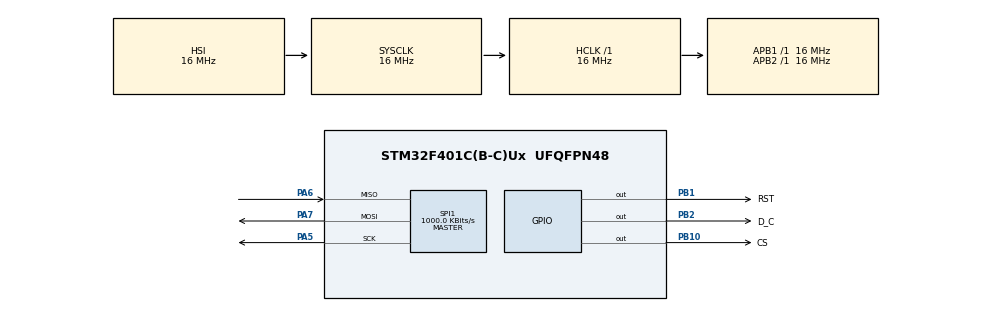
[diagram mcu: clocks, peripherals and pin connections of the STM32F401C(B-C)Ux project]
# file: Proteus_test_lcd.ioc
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Dma.Request0=SPI1_TX
Dma.SPI1_TX.0.Direction=DMA_MEMORY_TO_PERIPH
Dma.SPI1_TX.0.FIFOMode=DMA_FIFOMODE_DISABLE
Dma.SPI1_TX.0.Instance=DMA2_Stream3
Dma.SPI1_TX.0.MemDataAlignment=DMA_MDATAALIGN_BYTE
Dma.SPI1_TX.0.MemInc=DMA_MINC_ENABLE
Dma.SPI1_TX.0.Mode=DMA_NORMAL
Dma.SPI1_TX.0.PeriphDataAlignment=DMA_PDATAALIGN_BYTE
Dma.SPI1_TX.0.PeriphInc=DMA_PINC_DISABLE
Dma.SPI1_TX.0.Priority=DMA_PRIORITY_LOW
Mcu.Family=STM32F4
Mcu.Name=STM32F401C(B-C)Ux
Mcu.Package=UFQFPN48
NVIC.DMA2_Stream3_IRQn=true\:0\:0\:false\:false\:true\:false\:true\:true
NVIC.PriorityGroup=NVIC_PRIORITYGROUP_4
PA5.Mode=Full_Duplex_Master
PA5.Signal=SPI1_SCK
PA6.Mode=Full_Duplex_Master
PA6.Signal=SPI1_MISO
PA7.Mode=Full_Duplex_Master
PA7.Signal=SPI1_MOSI
PB1.GPIO_Label=RST
PB1.Signal=GPIO_Output
PB10.GPIO_Label=CS
PB10.Signal=GPIO_Output
PB2.GPIO_Label=D_C
PB2.Signal=GPIO_Output
ProjectManager.HeapSize=0x200
ProjectManager.StackSize=0x400
ProjectManager.TargetToolchain=STM32CubeIDE
RCC.AHBFreq_Value=16000000
RCC.APB1Freq_Value=16000000
RCC.APB2Freq_Value=16000000
RCC.CortexFreq_Value=16000000
RCC.HSE_VALUE=25000000
RCC.HSI_VALUE=16000000
RCC.LSE_VALUE=32768
RCC.SYSCLKFreq_VALUE=16000000
RCC.VCOOutputFreq_Value=192000000
SPI1.BaudRatePrescaler=SPI_BAUDRATEPRESCALER_16
SPI1.CalculateBaudRate=1000.0 KBits/s
SPI1.Direction=SPI_DIRECTION_2LINES
SPI1.Mode=SPI_MODE_MASTER
SPI1.VirtualType=VM_MASTER
board=custom

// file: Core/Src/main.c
/* USER CODE BEGIN Header */
/**
  ******************************************************************************
  * @file           : main.c
  * @brief          : Main program body
  ******************************************************************************
  * @attention
  *
  * Copyright (c) 2025 STMicroelectronics.
  * All rights reserved.
  *
  * This software is licensed under terms that can be found in the LICENSE file
  * in the root directory of this software component.
  * If no LICENSE file comes with this software, it is provided AS-IS.
  *
  ******************************************************************************
  */
/* USER CODE END Header */
#include "main.h"

/* USER CODE BEGIN Includes */
#include "ILI9341_STM32_DRIVER.h"
#include "ILI9341_GFX.h"
//#include "battery.h"
#include "allpic.h"
#include "stopwatch.h"
/* USER CODE END Includes */
#define IM_WEDTH 30
#define IM_HIGHT 60

SPI_HandleTypeDef hspi1;
DMA_HandleTypeDef hdma_spi1_tx;

void SystemClock_Config(void);
static void MX_GPIO_Init(void);
static void MX_DMA_Init(void);
static void MX_SPI1_Init(void);
void Display_LCD_UI(void);

int main(void)
{

  /* MCU Configuration--------------------------------------------------------*/

  /* Reset of all peripherals, Initializes the Flash interface and the Systick. */
  HAL_Init();

  /* Configure the system clock */
  SystemClock_Config();

  /* Initialize all configured peripherals */
  MX_GPIO_Init();
  MX_DMA_Init();
  MX_SPI1_Init();
  /* USER CODE BEGIN 2 */
  ILI9341_Init();
  HAL_Delay(1000);
//  ILI9341_DrawImageAt(image, 170, 2 , 60, 30);
//  ILI9341_DrawImageAt((const uint8_t*)stopwatch, 0, 0 , 40, 40);
  Display_LCD_UI();
  /* USER CODE END 2 */

  /* Infinite loop */
  while (1)
  {
//	  ILI9341_DrawImageAt((const uint8_t*)_less10, 170, 2 , IM_WEDTH, 60);
//	  HAL_Delay(1000);
//	  ILI9341_DrawImageAt((const uint8_t*)_20, 170, 2 , IM_WEDTH, IM_HIGHT);
//	  HAL_Delay(1000);
//	  ILI9341_DrawImageAt((const uint8_t*)_35, 170, 2 , IM_WEDTH, IM_HIGHT);
//	  HAL_Delay(1000);
//	  ILI9341_DrawImageAt((const uint8_t*)_50, 170, 2 , IM_WEDTH, IM_HIGHT);
//	  HAL_Delay(1000);
//	  ILI9341_DrawImageAt((const uint8_t*)_65, 170, 2 , IM_WEDTH, IM_HIGHT);
//	  HAL_Delay(1000);
//	  ILI9341_DrawImageAt((const uint8_t*)_85, 170, 2 , IM_WEDTH, IM_HIGHT);
//	  HAL_Delay(1000);
//	  ILI9341_DrawImageAt((const uint8_t*)_100, 170, 2 , IM_WEDTH, IM_HIGHT);
//	  HAL_Delay(1000);
//	  ILI9341_DrawImageAt((const uint8_t*)charging, 170, 2 , IM_WEDTH, IM_HIGHT);
//	  HAL_Delay(1000);
  }
}
void Display_LCD_UI(void)
{
    // Clear screen
    ILI9341_FillScreen(BLACK);

    // === TOP BAR ===
    ILI9341_DrawText("AMER 1", FONT3, 10, 10, RED, BLACK);                   // Top-left code
    ILI9341_DrawImageAt((const uint8_t*)_4, 210, 10, 20, 20);                                      // Top-right signal icon

    // === BATTERY 1 (Left) ===
    ILI9341_DrawImageAt((const uint8_t*)_less10, 20, 50, 30, 60);                                    // Battery icon
    ILI9341_DrawText("100%", FONT4, 70, 70, WHITE, BLACK);                 // Battery percentage
//    ILI9341_DrawText("SOC_RC", FONT3, 20, 30, WHITE, BLACK);             // Device name

    // === BATTERY 2 (Right) ===
    ILI9341_DrawImageAt((const uint8_t*)_85, 140, 50, 30, 60);                                   // Battery icon
    ILI9341_DrawText("100%", FONT4, 190, 70, WHITE, BLACK);                // Battery percentage
//    ILI9341_DrawText("ROBOT ", FONT3, 140, 30, WHITE, BLACK);          // Device name

    // === DIVIDER ===
//    ILI9341_DrawHLine(0, 220, 240, WHITE);                                          // Horizontal line
//    ILI9341_DrawHLine(0, 221, 240, WHITE);                                          // Horizontal line
//    ILI9341_DrawHLine(0, 222, 240, WHITE);                                          // Horizontal line
//    ILI9341_DrawHLine(0, 222, 240, WHITE);                                          // Horizontal line

    // === STOPWATCH AREA ===
    ILI9341_DrawText("STOP-WATCH", FONT3, 75, 260, WHITE, BLACK);         // Label
    ILI9341_DrawText("00:00", FONT4, 100, 280, WHITE, BLACK);              // Timer text
//    ILI9341_DrawImageAt((const uint8_t*)stopwatch, 95, 180, 50, 60);                                   // Stopwatch icon
    ILI9341_DrawMonoImageAt(gImage_finals, 95, 180, 50, 60, 0x0000, 0xFEA0);

}

void SystemClock_Config(void)
{
  RCC_OscInitTypeDef RCC_OscInitStruct = {0};
  RCC_ClkInitTypeDef RCC_ClkInitStruct = {0};

  /** Configure the main internal regulator output voltage
  */
  __HAL_RCC_PWR_CLK_ENABLE();
  __HAL_PWR_VOLTAGESCALING_CONFIG(PWR_REGULATOR_VOLTAGE_SCALE2);

  /** Initializes the RCC Oscillators according to the specified parameters
  * in the RCC_OscInitTypeDef structure.
  */
  RCC_OscInitStruct.OscillatorType = RCC_OSCILLATORTYPE_HSI;
  RCC_OscInitStruct.HSIState = RCC_HSI_ON;
  RCC_OscInitStruct.HSICalibrationValue = RCC_HSICALIBRATION_DEFAULT;
  RCC_OscInitStruct.PLL.PLLState = RCC_PLL_NONE;
  if (HAL_RCC_OscConfig(&RCC_OscInitStruct) != HAL_OK)
  {
    Error_Handler();
  }

  /** Initializes the CPU, AHB and APB buses clocks
  */
  RCC_ClkInitStruct.ClockType = RCC_CLOCKTYPE_HCLK|RCC_CLOCKTYPE_SYSCLK
                              |RCC_CLOCKTYPE_PCLK1|RCC_CLOCKTYPE_PCLK2;
  RCC_ClkInitStruct.SYSCLKSource = RCC_SYSCLKSOURCE_HSI;
  RCC_ClkInitStruct.AHBCLKDivider = RCC_SYSCLK_DIV1;
  RCC_ClkInitStruct.APB1CLKDivider = RCC_HCLK_DIV1;
  RCC_ClkInitStruct.APB2CLKDivider = RCC_HCLK_DIV1;

  if (HAL_RCC_ClockConfig(&RCC_ClkInitStruct, FLASH_LATENCY_0) != HAL_OK)
  {
    Error_Handler();
  }
}

static void MX_SPI1_Init(void)
{

  /* SPI1 parameter configuration*/
  hspi1.Instance = SPI1;
  hspi1.Init.Mode = SPI_MODE_MASTER;
  hspi1.Init.Direction = SPI_DIRECTION_2LINES;
  hspi1.Init.DataSize = SPI_DATASIZE_8BIT;
  hspi1.Init.CLKPolarity = SPI_POLARITY_LOW;
  hspi1.Init.CLKPhase = SPI_PHASE_1EDGE;
  hspi1.Init.NSS = SPI_NSS_SOFT;
  hspi1.Init.BaudRatePrescaler = SPI_BAUDRATEPRESCALER_16;
  hspi1.Init.FirstBit = SPI_FIRSTBIT_MSB;
  hspi1.Init.TIMode = SPI_TIMODE_DISABLE;
  hspi1.Init.CRCCalculation = SPI_CRCCALCULATION_DISABLE;
  hspi1.Init.CRCPolynomial = 10;
  if (HAL_SPI_Init(&hspi1) != HAL_OK)
  {
    Error_Handler();
  }

}

static void MX_DMA_Init(void)
{

  /* DMA controller clock enable */
  __HAL_RCC_DMA2_CLK_ENABLE();

  /* DMA interrupt init */
  /* DMA2_Stream3_IRQn interrupt configuration */
  HAL_NVIC_SetPriority(DMA2_Stream3_IRQn, 0, 0);
  HAL_NVIC_EnableIRQ(DMA2_Stream3_IRQn);

}

static void MX_GPIO_Init(void)
{
  GPIO_InitTypeDef GPIO_InitStruct = {0};

  /* GPIO Ports Clock Enable */
  __HAL_RCC_GPIOA_CLK_ENABLE();
  __HAL_RCC_GPIOB_CLK_ENABLE();

  /*Configure GPIO pin Output Level */
  HAL_GPIO_WritePin(GPIOB, RST_Pin|D_C_Pin|CS_Pin, GPIO_PIN_RESET);

  /*Configure GPIO pins : RST_Pin D_C_Pin CS_Pin */
  GPIO_InitStruct.Pin = RST_Pin|D_C_Pin|CS_Pin;
  GPIO_InitStruct.Mode = GPIO_MODE_OUTPUT_PP;
  GPIO_InitStruct.Pull = GPIO_NOPULL;
  GPIO_InitStruct.Speed = GPIO_SPEED_FREQ_LOW;
  HAL_GPIO_Init(GPIOB, &GPIO_InitStruct);

}

void Error_Handler(void)
{
  __disable_irq();
  while (1)
  {
  }
}
